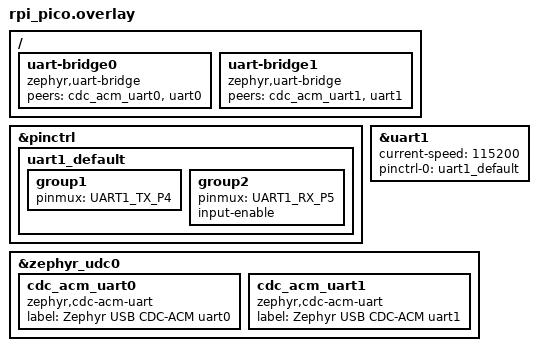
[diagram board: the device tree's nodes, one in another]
/ {
	uart-bridge0 {
		compatible = "zephyr,uart-bridge";
		peers = <&cdc_acm_uart0 &uart0>;
	};

	uart-bridge1 {
		compatible = "zephyr,uart-bridge";
		peers = <&cdc_acm_uart1 &uart1>;
	};
};

&pinctrl {
	uart1_default: uart1_default {
		group1 {
			pinmux = <UART1_TX_P4>;
		};
		group2 {
			pinmux = <UART1_RX_P5>;
			input-enable;
		};
	};
};

&uart1 {
	current-speed = <115200>;
	status = "okay";
	pinctrl-0 = <&uart1_default>;
	pinctrl-names = "default";
};

&zephyr_udc0 {
	cdc_acm_uart0: cdc_acm_uart0 {
		compatible = "zephyr,cdc-acm-uart";
		label = "Zephyr USB CDC-ACM uart0";
	};

	cdc_acm_uart1: cdc_acm_uart1 {
		compatible = "zephyr,cdc-acm-uart";
		label = "Zephyr USB CDC-ACM uart1";
	};
};
